# ATtiny861A register map
Vendor: Atmel; File version: 1.0
CPU: other r0p0, little endian, no MPU, no FPU, 4 interrupt priority bits
Registers are 8-bit, read-write, reset 0x0 unless marked. A register's access mark holds for its fields unless they carry their own. Offsets are from the block's base; [hi:lo] are bit positions.

## BOOT_LOAD — Bootloader
Base 0x00800057
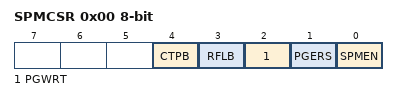
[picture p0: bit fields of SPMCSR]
0x00 SPMCSR — Store Program Memory Control Register (read-only for debugger)
  [4] CTPB — Clear temporary page buffer
  [3] RFLB — Read fuse and lock bits
  [2] PGWRT — Page Write
  [1] PGERS — Page Erase
  [0] SPMEN — Store Program Memory Enable

## CPU — CPU Registers
Base 0x0080002A
0x00 GPIOR0 — General purpose register 0
0x01 GPIOR1 — General Purpose register 1
0x02 GPIOR2 — General Purpose IO register 2
0x16 DWDR — debugWire data register (write-only for debugger)
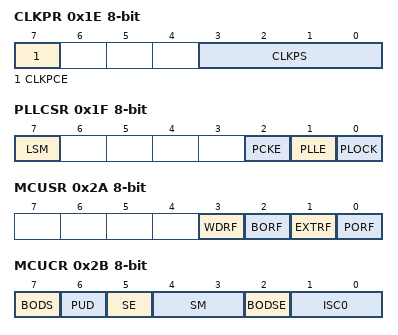
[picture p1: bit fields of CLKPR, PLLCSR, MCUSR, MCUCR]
0x1E CLKPR — Clock Prescale Register (read-only for debugger)
  [7] CLKPCE — Clock Prescaler Change Enable
  [3:0] CLKPS — Clock Prescaler Select Bits
    0=1; 1=2; 2=4; 3=8; 4=16; 5=32; 6=64; 7=128; 8=256
0x1F PLLCSR — PLL Control and status register
  [7] LSM — Low speed mode
  [2] PCKE — PCK Enable
  [1] PLLE — PLL Enable
  [0] PLOCK — PLL Lock detector
0x27 OSCCAL — Oscillator Calibration Register (read-only for debugger)
  [7:0] OSCCAL — Oscillator Calibration
0x2A MCUSR — MCU Status register
  [3] WDRF — Watchdog Reset Flag
  [2] BORF — Brown-out Reset Flag
  [1] EXTRF — External Reset Flag
  [0] PORF — Power-On Reset Flag
0x2B MCUCR — MCU Control Register
  [7] BODS — BOD Sleep
  [6] PUD — Pull-up Disable
  [5] SE — Sleep Enable
  [4:3] SM — Sleep Mode Select Bits
    0=IDLE; 1=ADC (ADC Noise Reduction (If Available)); 2=PDOWN (Power Down); 3=STDBY (Standby)
  [2] BODSE — BOD Sleep Enable
  [1:0] ISC0 — Interrupt Sense Control 0 bits
    0=LOW_LEVEL_OF_INTX; 1=ANY_LOGICAL_CHANGE_IN_INTX; 2=FALLING_EDGE_OF_INTX; 3=RISING_EDGE_OF_INTX
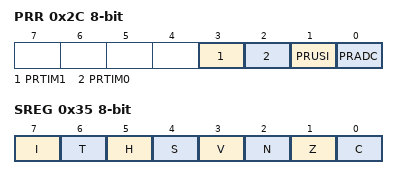
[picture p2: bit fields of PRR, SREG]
0x2C PRR — Power Reduction Register
  [3] PRTIM1 — Power Reduction Timer/Counter1
  [2] PRTIM0 — Power Reduction Timer/Counter0
  [1] PRUSI — Power Reduction USI
  [0] PRADC — Power Reduction ADC
0x33 SP 16-bit (reset mask 0xFF) — Stack Pointer Bytes
0x35 SREG — Status Register
  [7] I — Global Interrupt Enable
  [6] T — Bit Copy Storage
  [5] H — Half Carry Flag
  [4] S — Sign Bit
  [3] V — Two's Complement Overflow Flag
  [2] N — Negative Flag
  [1] Z — Zero Flag
  [0] C — Carry Flag

## EEPROM
Base 0x0080003C
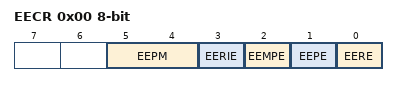
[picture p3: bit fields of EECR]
0x00 EECR — EEPROM Control Register
  [5:4] EEPM — EEPROM Programming Mode Bits
    0=ERASE_AND_WRITE_IN_ONE_OPERATION; 1=ERASE_ONLY; 2=WRITE_ONLY
  [3] EERIE — EEPROM Ready Interrupt Enable
  [2] EEMPE — EEPROM Master Write Enable
  [1] EEPE — EEPROM Write Enable
  [0] EERE — EEPROM Read Enable
0x01 EEDR — EEPROM Data Register
0x02 EEAR 16-bit (reset mask 0xFF) — EEPROM Address Register Bytes

## EXINT — External Interrupts
Base 0x00800042
0x00 PCMSK1 — Pin Change Enable Mask 1
0x01 PCMSK0 — Pin Change Enable Mask 0
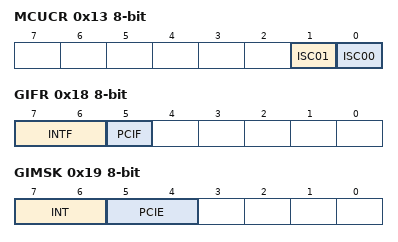
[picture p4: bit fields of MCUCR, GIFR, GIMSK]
0x13 MCUCR — MCU Control Register
  [1] ISC01 — Interrupt Sense Control 0 Bit 1
  [0] ISC00 — Interrupt Sense Control 0 Bit 0
    0=LOW_LEVEL_OF_INTX; 1=ANY_LOGICAL_CHANGE_OF_INTX
0x18 GIFR — General Interrupt Flag register (read-only for debugger)
  [7:6] INTF — External Interrupt Flags
  [5] PCIF — Pin Change Interrupt Flag
0x19 GIMSK — General Interrupt Mask Register
  [7:6] INT — External Interrupt Request 1 Enable
  [5:4] PCIE — Pin Change Interrupt Enables

## PORTA — I/O Port
Base 0x00800039
0x00 PINA — Port A Input Pins (read-only for debugger)
0x01 DDRA — Port A Data Direction Register
0x02 PORTA — Port A Data Register

## PORTB — I/O Port
Base 0x00800036
0x00 PINB — Port B Input Pins (read-only for debugger)
0x01 DDRB — Port B Data Direction Register
0x02 PORTB — Port B Data Register

## TC0 — Timer/Counter, 8-bit
Base 0x00800032
0x00 OCR0B — Timer/Counter0 Output Compare Register
0x01 OCR0A — Timer/Counter0 Output Compare Register
0x02 TCNT0H — Timer/Counter0 High
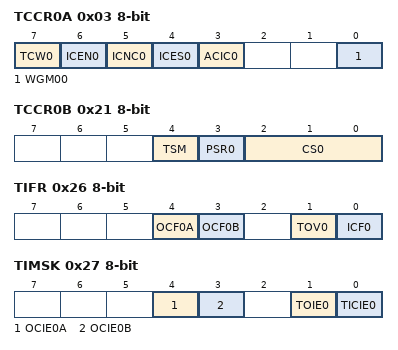
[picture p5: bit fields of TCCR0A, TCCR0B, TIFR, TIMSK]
0x03 TCCR0A — Timer/Counter Control Register A
  [7] TCW0 — Timer/Counter 0 Width
  [6] ICEN0 — Input Capture Mode Enable
  [5] ICNC0 — Input Capture Noise Canceler
  [4] ICES0 — Input Capture Edge Select
  [3] ACIC0 — Analog Comparator Input Capture Enable
  [0] WGM00 — Waveform Generation Mode
0x20 TCNT0L — Timer/Counter0 Low
0x21 TCCR0B — Timer/Counter Control Register B
  [4] TSM — Timer/Counter Synchronization Mode
  [3] PSR0 — Timer/Counter 0 Prescaler Reset
  [2:0] CS0 — Clock Select
    0=NO_CLOCK_SOURCE_STOPPED; 1=RUNNING_NO_PRESCALING; 2=RUNNING_CLK_8; 3=RUNNING_CLK_64; 4=RUNNING_CLK_256; 5=RUNNING_CLK_1024; 6=RUNNING_EXTCLK_TN_FALLING_EDGE; 7=RUNNING_EXTCLK_TN_RISING_EDGE
0x26 TIFR — Timer/Counter0 Interrupt Flag register (read-only for debugger)
  [4] OCF0A — Timer/Counter0 Output Compare Flag 0A
  [3] OCF0B — Timer/Counter0 Output Compare Flag 0B
  [1] TOV0 — Timer/Counter0 Overflow Flag
  [0] ICF0 — Timer/Counter0 Input Capture Flag
0x27 TIMSK — Timer/Counter Interrupt Mask Register
  [4] OCIE0A — Timer/Counter0 Output Compare Match A Interrupt Enable
  [3] OCIE0B — Timer/Counter0 Output Compare Match B Interrupt Enable
  [1] TOIE0 — Timer/Counter0 Overflow Interrupt Enable
  [0] TICIE0 — Timer/Counter0 Input Capture Interrupt Enable
